# N32H7xx register map
Vendor: Nationstech Ltd.; File version: 1.0
CPU: CM7 r1p1, little endian, MPU, FPU, 4 interrupt priority bits
Registers are 32-bit, read-write, reset 0x0 unless marked. A register's access mark holds for its fields unless they carry their own. Offsets are from the block's base; [hi:lo] are bit positions; {n}, {i} and the like mark numbered series.

## GPU — Graphics processing unit
Base 0x50040000
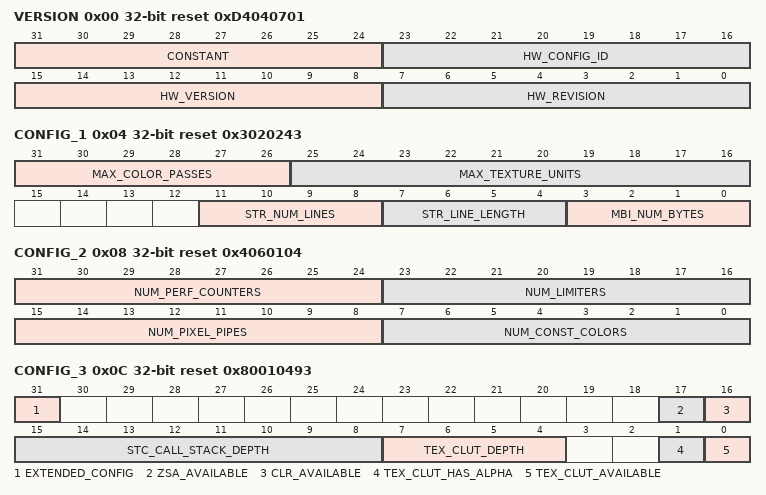
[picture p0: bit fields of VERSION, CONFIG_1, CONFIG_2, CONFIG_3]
0x00 VERSION ro reset 0xD4040701
  [31:24] CONSTANT, [23:16] HW_CONFIG_ID, [15:8] HW_VERSION, [7:0] HW_REVISION
0x04 CONFIG_1 ro reset 0x3020243
  [31:26] MAX_COLOR_PASSES, [25:16] MAX_TEXTURE_UNITS, [11:8] STR_NUM_LINES, [7:4] STR_LINE_LENGTH, [3:0] MBI_NUM_BYTES
0x08 CONFIG_2 ro reset 0x4060104
  [31:24] NUM_PERF_COUNTERS, [23:16] NUM_LIMITERS, [15:8] NUM_PIXEL_PIPES, [7:0] NUM_CONST_COLORS
0x0C CONFIG_3 ro reset 0x80010493
  [31] EXTENDED_CONFIG, [17] ZSA_AVAILABLE, [16] CLR_AVAILABLE, [15:8] STC_CALL_STACK_DEPTH, [7:4] TEX_CLUT_DEPTH, [1] TEX_CLUT_HAS_ALPHA, [0] TEX_CLUT_AVAILABLE
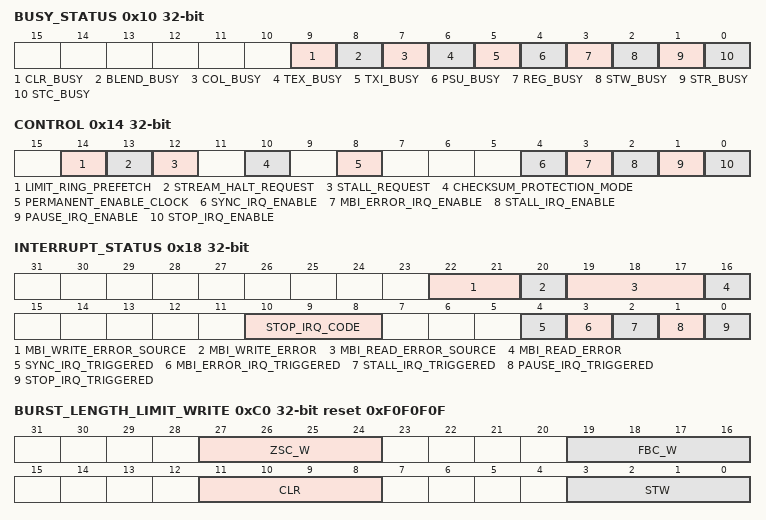
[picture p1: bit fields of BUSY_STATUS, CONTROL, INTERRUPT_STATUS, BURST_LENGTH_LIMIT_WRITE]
0x10 BUSY_STATUS ro
  [9] CLR_BUSY, [8] BLEND_BUSY, [7] COL_BUSY, [6] TEX_BUSY, [5] TXI_BUSY, [4] PSU_BUSY, [3] REG_BUSY, [2] STW_BUSY, [1] STR_BUSY, [0] STC_BUSY
0x14 CONTROL
  [14] LIMIT_RING_PREFETCH, [13] STREAM_HALT_REQUEST, [12] STALL_REQUEST, [10] CHECKSUM_PROTECTION_MODE, [8] PERMANENT_ENABLE_CLOCK, [4] SYNC_IRQ_ENABLE, [3] MBI_ERROR_IRQ_ENABLE, [2] STALL_IRQ_ENABLE, [1] PAUSE_IRQ_ENABLE, [0] STOP_IRQ_ENABLE
0x18 INTERRUPT_STATUS
  [22:21] MBI_WRITE_ERROR_SOURCE ro, [20] MBI_WRITE_ERROR ro, [19:17] MBI_READ_ERROR_SOURCE ro, [16] MBI_READ_ERROR ro, [10:8] STOP_IRQ_CODE ro, [4] SYNC_IRQ_TRIGGERED write-1-clears, [3] MBI_ERROR_IRQ_TRIGGERED write-1-clears, [2] STALL_IRQ_TRIGGERED write-1-clears, [1] PAUSE_IRQ_TRIGGERED write-1-clears, [0] STOP_IRQ_TRIGGERED write-1-clears
0x1C STREAM_ADDRESS
  [31:2] STREAM_ADDRESS
0x20 RING_PAUSE_ADDRESS
  [31:2] RING_PAUSE_ADDRESS
0x24 CURRENT_RING_ADDRESS
  [31:2] CURRENT_RING_ADDRESS
0x28 CURRENT_STREAM_ADDRESS
  [31:2] CURRENT_STREAM_ADDRESS
0x2C CURRENT_CHECKSUM
  [31:0] CURRENT_REFERENCE_CHECKSUM
{0x30+4i} SYNC_ID_{i} (i=0..2)
  [31:0] SYNCHRONIZATION_ID_{i}
0x3C CALL_STACK_POINTER
  [1:0] CALL_STACK_POINTER
{0x40+4i} CALL_STACK_ENTRY_{i} (i=0..7)
  [31:2] CALL_STACK_ENTRY_{i}
{0x80+4i} PERFORMANCE_COUNTER_VALUES_{i} ro (i=0..3)
0xC0 BURST_LENGTH_LIMIT_WRITE reset 0xF0F0F0F
  [27:24] ZSC_W, [19:16] FBC_W, [11:8] CLR, [3:0] STW
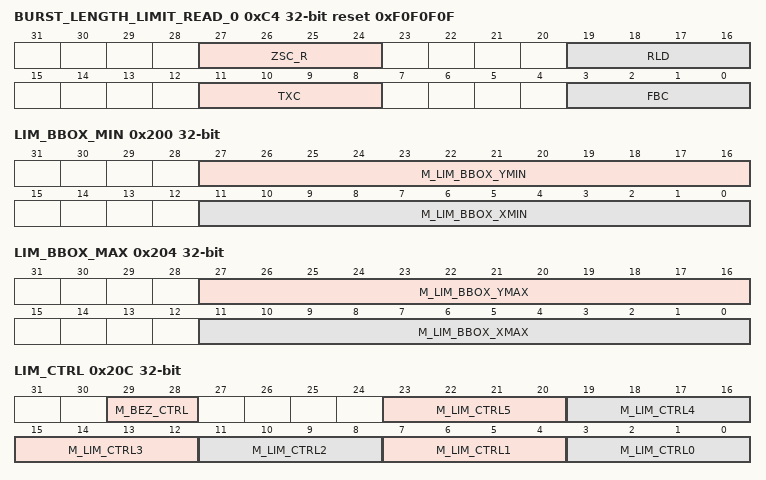
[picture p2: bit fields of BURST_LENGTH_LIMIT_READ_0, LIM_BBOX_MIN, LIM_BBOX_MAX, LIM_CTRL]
0xC4 BURST_LENGTH_LIMIT_READ_0 reset 0xF0F0F0F
  [27:24] ZSC_R, [19:16] RLD, [11:8] TXC, [3:0] FBC
0xC8 BURST_LENGTH_LIMIT_READ_1 reset 0xF
  [3:0] STR
0x200 LIM_BBOX_MIN
  [27:16] M_LIM_BBOX_YMIN, [11:0] M_LIM_BBOX_XMIN
0x204 LIM_BBOX_MAX
  [27:16] M_LIM_BBOX_YMAX, [11:0] M_LIM_BBOX_XMAX
0x208 LIM_START
  [27:16] M_LIM_START_Y
0x20C LIM_CTRL
  [29:28] M_BEZ_CTRL, [4n+3:4n] M_LIM_CTRL{n} (n=0..5)
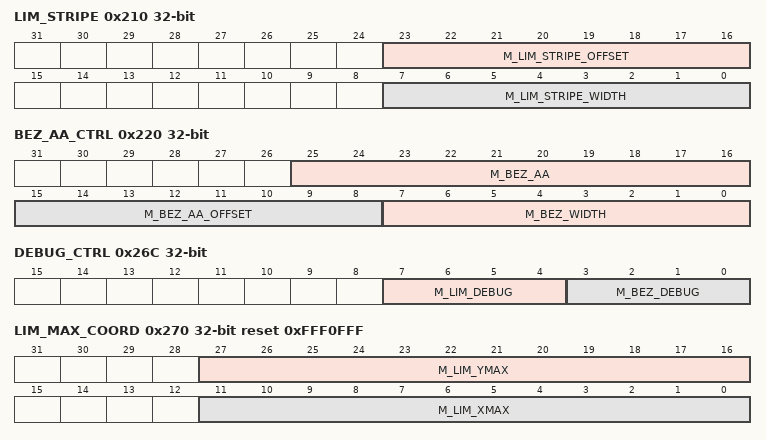
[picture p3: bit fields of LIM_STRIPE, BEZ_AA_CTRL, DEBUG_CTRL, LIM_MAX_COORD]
0x210 LIM_STRIPE
  [23:16] M_LIM_STRIPE_OFFSET, [7:0] M_LIM_STRIPE_WIDTH
0x214 BEZ_CTRL
  [5:0] M_BEZ_LIM_SCALE
0x218 BEZ_VOFF_0
  [31:0] M_BEZ_VOFF_0
0x21C BEZ_VOFF_1
  [31:0] M_BEZ_VOFF_1
0x220 BEZ_AA_CTRL
  [25:16] M_BEZ_AA, [15:8] M_BEZ_AA_OFFSET, [7:0] M_BEZ_WIDTH
{0x224+0xC*i} LIM_VSTART_{i} (i=0..5)
  [31:0] M_LIM_VSTART_{i}
{0x228+0xC*i} LIM_DX_{i} (i=0..5)
  [19:0] M_LIM_DX_{i}
{0x22C+0xC*i} LIM_DY_{i} (i=0..5)
  [19:0] M_LIM_DY_{i}
0x26C DEBUG_CTRL
  [7:4] M_LIM_DEBUG, [3:0] M_BEZ_DEBUG
0x270 LIM_MAX_COORD reset 0xFFF0FFF
  [27:16] M_LIM_YMAX, [11:0] M_LIM_XMAX
0x300 TXA_U_OFFSET_0
  [31:0] M_TXA_U_OFFSET_0
0x304 TXA_V_OFFSET_0
  [31:0] M_TXA_V_OFFSET_0
0x308 TXA_DUX_0 reset 0x3F800000
  [31:0] M_TXA_DUX_0
0x30C TXA_DUY_0
  [31:0] M_TXA_DUY_0
0x310 TXA_DVX_0
  [31:0] M_TXA_DVX_0
0x314 TXA_DVY_0 reset 0x3F800000
  [31:0] M_TXA_DVY_0
0x318 TXA_U_OFFSET_1
  [31:0] M_TXA_U_OFFSET_1
0x31C TXA_V_OFFSET_1
  [31:0] M_TXA_V_OFFSET_1
0x320 TXA_DUX_1 reset 0x3F800000
  [31:0] M_TXA_DUX_1
0x324 TXA_DUY_1
  [31:0] M_TXA_DUY_1
0x328 TXA_DVX_1
  [31:0] M_TXA_DVX_1
0x32C TXA_DVY_1 reset 0x3F800000
  [31:0] M_TXA_DVY_1
0x408 TXA_Z_OFFSET
  [31:0] M_TXA_Z_OFFSET
0x40C TXA_DZX
  [31:0] M_TXA_DZX
0x410 TXA_DZY
  [31:0] M_TXA_DZY
0x414 TXA_Z_RHW_OFFSET reset 0x3F800000
  [31:0] M_TXA_Z_RHW_OFFSET
0x418 TXA_Z_DRHWX
  [31:0] M_TXA_Z_DRHWX
0x41C TXA_Z_DRHWY
  [31:0] M_TXA_Z_DRHWY
0x420 TXA_RHW_OFFSET_0 reset 0x3F800000
  [31:0] M_TXA_RHW_OFFSET_0
0x424 TXA_DRHWX_0
  [31:0] M_TXA_DRHWX_0
0x428 TXA_DRHWY_0
  [31:0] M_TXA_DRHWY_0
0x42C TXA_RHW_OFFSET_1 reset 0x3F800000
  [31:0] M_TXA_RHW_OFFSET_1
0x430 TXA_DRHWX_1
  [31:0] M_TXA_DRHWX_1
0x434 TXA_DRHWY_1
  [31:0] M_TXA_DRHWY_1
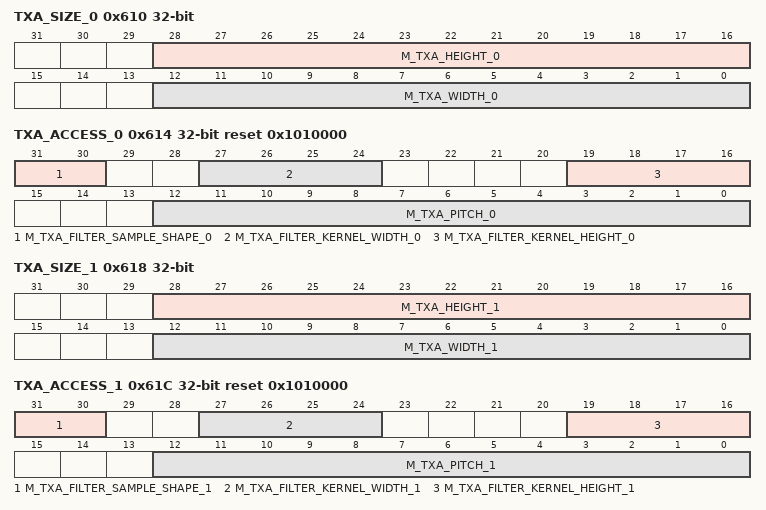
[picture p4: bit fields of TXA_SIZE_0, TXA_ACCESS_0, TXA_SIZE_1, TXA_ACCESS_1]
0x610 TXA_SIZE_0
  [28:16] M_TXA_HEIGHT_0, [12:0] M_TXA_WIDTH_0
0x614 TXA_ACCESS_0 reset 0x1010000
  [31:30] M_TXA_FILTER_SAMPLE_SHAPE_0, [27:24] M_TXA_FILTER_KERNEL_WIDTH_0, [19:16] M_TXA_FILTER_KERNEL_HEIGHT_0, [12:0] M_TXA_PITCH_0
0x618 TXA_SIZE_1
  [28:16] M_TXA_HEIGHT_1, [12:0] M_TXA_WIDTH_1
0x61C TXA_ACCESS_1 reset 0x1010000
  [31:30] M_TXA_FILTER_SAMPLE_SHAPE_1, [27:24] M_TXA_FILTER_KERNEL_WIDTH_1, [19:16] M_TXA_FILTER_KERNEL_HEIGHT_1, [12:0] M_TXA_PITCH_1
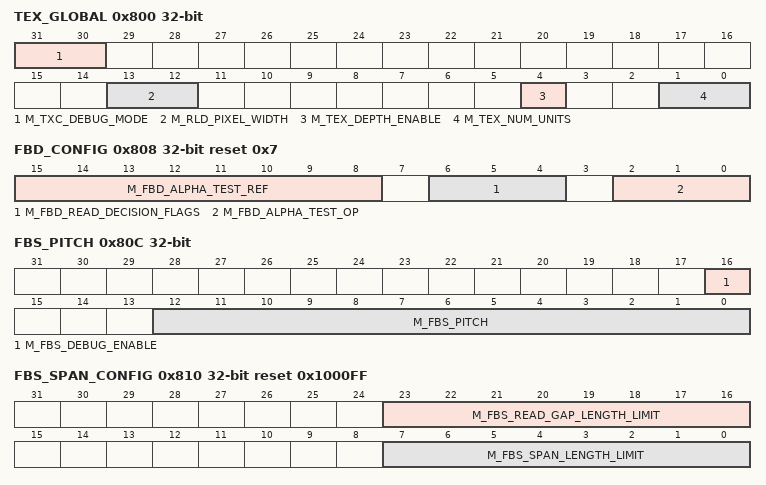
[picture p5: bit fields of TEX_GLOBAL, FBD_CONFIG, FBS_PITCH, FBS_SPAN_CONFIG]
0x800 TEX_GLOBAL
  [31:30] M_TXC_DEBUG_MODE, [13:12] M_RLD_PIXEL_WIDTH, [4] M_TEX_DEPTH_ENABLE, [1:0] M_TEX_NUM_UNITS
0x804 COL_GLOBAL reset 0x1
  [2:0] M_COL_NUM_PASSES
0x808 FBD_CONFIG reset 0x7
  [15:8] M_FBD_ALPHA_TEST_REF, [6:4] M_FBD_READ_DECISION_FLAGS, [2:0] M_FBD_ALPHA_TEST_OP
0x80C FBS_PITCH
  [16] M_FBS_DEBUG_ENABLE, [12:0] M_FBS_PITCH
0x810 FBS_SPAN_CONFIG reset 0x1000FF
  [23:16] M_FBS_READ_GAP_LENGTH_LIMIT, [7:0] M_FBS_SPAN_LENGTH_LIMIT
0x814 RLD_START_ADDRESS
  [31:0] M_RLD_START_ADDRESS
{0x818+4i} COL_CONST_COLOR_{i} reset 0xFFFFFFFF (i=0..3)
  [31:0] M_COL_CONST_COLOR_{i}
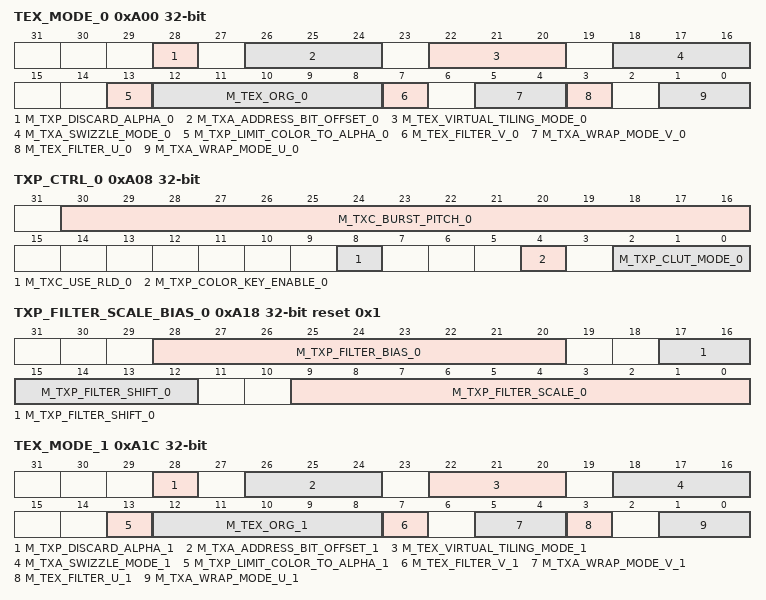
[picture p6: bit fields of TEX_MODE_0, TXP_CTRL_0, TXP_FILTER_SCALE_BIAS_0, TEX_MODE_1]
0xA00 TEX_MODE_0
  [28] M_TXP_DISCARD_ALPHA_0, [26:24] M_TXA_ADDRESS_BIT_OFFSET_0, [22:20] M_TEX_VIRTUAL_TILING_MODE_0, [18:16] M_TXA_SWIZZLE_MODE_0, [13] M_TXP_LIMIT_COLOR_TO_ALPHA_0, [12:8] M_TEX_ORG_0, [7] M_TEX_FILTER_V_0, [5:4] M_TXA_WRAP_MODE_V_0, [3] M_TEX_FILTER_U_0, [1:0] M_TXA_WRAP_MODE_U_0
0xA04 TXC_START_ADDRESS_0
  [31:0] M_TXC_START_ADDRESS_0
0xA08 TXP_CTRL_0
  [30:16] M_TXC_BURST_PITCH_0, [8] M_TXC_USE_RLD_0, [4] M_TXP_COLOR_KEY_ENABLE_0, [2:0] M_TXP_CLUT_MODE_0
0xA0C TXP_CLUT_OFFSET_0
  [8:0] M_TXP_CLUT_OFFSET_0
0xA10 TXP_COLOR_KEY_0
  [23:0] M_TXP_COLOR_KEY_0
0xA14 TXP_FILL_COLOR_0
  [31:0] M_TXP_FILL_COLOR_0
0xA18 TXP_FILTER_SCALE_BIAS_0 reset 0x1
  [28:20] M_TXP_FILTER_BIAS_0, [17:12] M_TXP_FILTER_SHIFT_0, [9:0] M_TXP_FILTER_SCALE_0
0xA1C TEX_MODE_1
  [28] M_TXP_DISCARD_ALPHA_1, [26:24] M_TXA_ADDRESS_BIT_OFFSET_1, [22:20] M_TEX_VIRTUAL_TILING_MODE_1, [18:16] M_TXA_SWIZZLE_MODE_1, [13] M_TXP_LIMIT_COLOR_TO_ALPHA_1, [12:8] M_TEX_ORG_1, [7] M_TEX_FILTER_V_1, [5:4] M_TXA_WRAP_MODE_V_1, [3] M_TEX_FILTER_U_1, [1:0] M_TXA_WRAP_MODE_U_1
0xA20 TXC_START_ADDRESS_1
  [31:0] M_TXC_START_ADDRESS_1
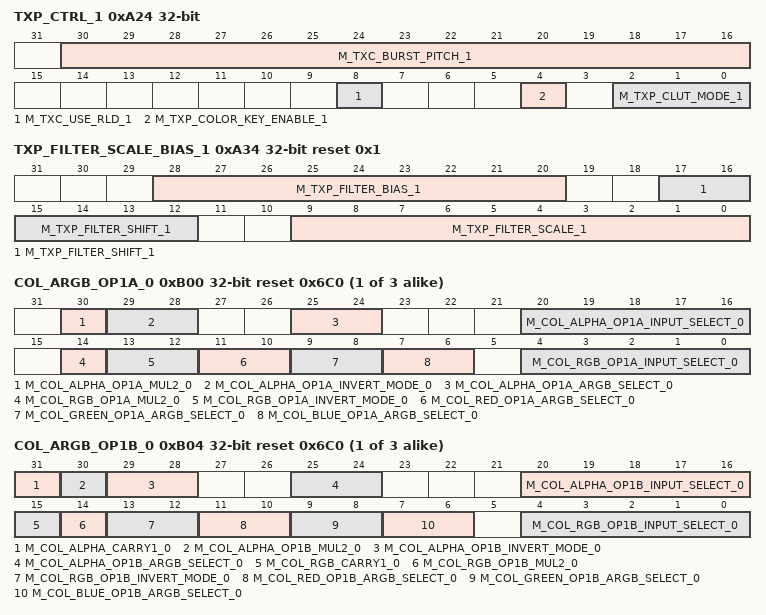
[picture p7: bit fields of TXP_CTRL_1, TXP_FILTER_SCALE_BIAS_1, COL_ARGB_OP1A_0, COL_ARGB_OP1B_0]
0xA24 TXP_CTRL_1
  [30:16] M_TXC_BURST_PITCH_1, [8] M_TXC_USE_RLD_1, [4] M_TXP_COLOR_KEY_ENABLE_1, [2:0] M_TXP_CLUT_MODE_1
0xA28 TXP_CLUT_OFFSET_1
  [8:0] M_TXP_CLUT_OFFSET_1
0xA2C TXP_COLOR_KEY_1
  [23:0] M_TXP_COLOR_KEY_1
0xA30 TXP_FILL_COLOR_1
  [31:0] M_TXP_FILL_COLOR_1
0xA34 TXP_FILTER_SCALE_BIAS_1 reset 0x1
  [28:20] M_TXP_FILTER_BIAS_1, [17:12] M_TXP_FILTER_SHIFT_1, [9:0] M_TXP_FILTER_SCALE_1
{0xB00+0x18*i} COL_ARGB_OP1A_{i} reset 0x6C0 (i=0..2)
  [30] M_COL_ALPHA_OP1A_MUL2_{i}, [29:28] M_COL_ALPHA_OP1A_INVERT_MODE_{i}, [25:24] M_COL_ALPHA_OP1A_ARGB_SELECT_{i}, [20:16] M_COL_ALPHA_OP1A_INPUT_SELECT_{i}, [14] M_COL_RGB_OP1A_MUL2_{i}, [13:12] M_COL_RGB_OP1A_INVERT_MODE_{i}, [11:10] M_COL_RED_OP1A_ARGB_SELECT_{i}, [9:8] M_COL_GREEN_OP1A_ARGB_SELECT_{i}, [7:6] M_COL_BLUE_OP1A_ARGB_SELECT_{i}, [4:0] M_COL_RGB_OP1A_INPUT_SELECT_{i}
{0xB04+0x18*i} COL_ARGB_OP1B_{i} reset 0x6C0 (i=0..2)
  [31] M_COL_ALPHA_CARRY1_{i}, [30] M_COL_ALPHA_OP1B_MUL2_{i}, [29:28] M_COL_ALPHA_OP1B_INVERT_MODE_{i}, [25:24] M_COL_ALPHA_OP1B_ARGB_SELECT_{i}, [20:16] M_COL_ALPHA_OP1B_INPUT_SELECT_{i}, [15] M_COL_RGB_CARRY1_{i}, [14] M_COL_RGB_OP1B_MUL2_{i}, [13:12] M_COL_RGB_OP1B_INVERT_MODE_{i}, [11:10] M_COL_RED_OP1B_ARGB_SELECT_{i}, [9:8] M_COL_GREEN_OP1B_ARGB_SELECT_{i}, [7:6] M_COL_BLUE_OP1B_ARGB_SELECT_{i}, [4:0] M_COL_RGB_OP1B_INPUT_SELECT_{i}
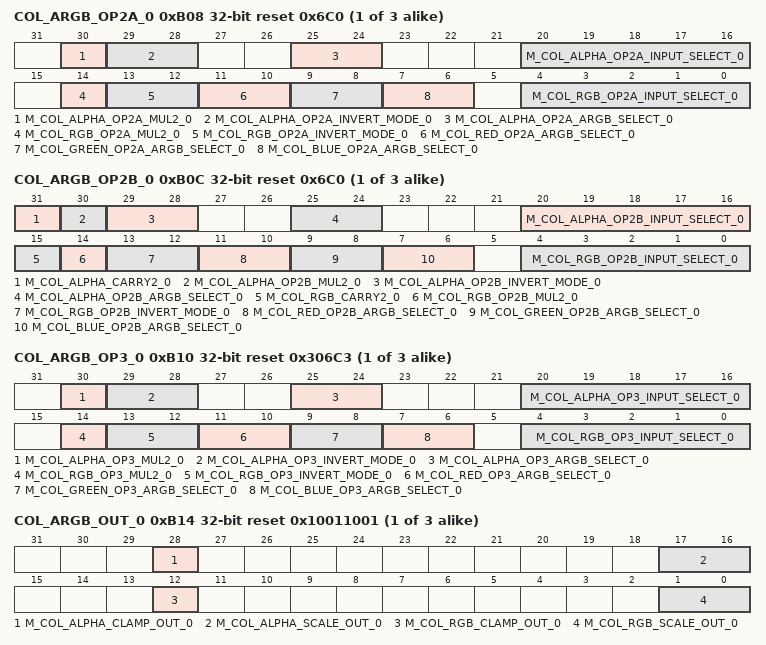
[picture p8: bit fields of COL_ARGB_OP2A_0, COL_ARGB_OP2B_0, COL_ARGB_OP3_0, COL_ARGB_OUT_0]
{0xB08+0x18*i} COL_ARGB_OP2A_{i} reset 0x6C0 (i=0..2)
  [30] M_COL_ALPHA_OP2A_MUL2_{i}, [29:28] M_COL_ALPHA_OP2A_INVERT_MODE_{i}, [25:24] M_COL_ALPHA_OP2A_ARGB_SELECT_{i}, [20:16] M_COL_ALPHA_OP2A_INPUT_SELECT_{i}, [14] M_COL_RGB_OP2A_MUL2_{i}, [13:12] M_COL_RGB_OP2A_INVERT_MODE_{i}, [11:10] M_COL_RED_OP2A_ARGB_SELECT_{i}, [9:8] M_COL_GREEN_OP2A_ARGB_SELECT_{i}, [7:6] M_COL_BLUE_OP2A_ARGB_SELECT_{i}, [4:0] M_COL_RGB_OP2A_INPUT_SELECT_{i}
{0xB0C+0x18*i} COL_ARGB_OP2B_{i} reset 0x6C0 (i=0..2)
  [31] M_COL_ALPHA_CARRY2_{i}, [30] M_COL_ALPHA_OP2B_MUL2_{i}, [29:28] M_COL_ALPHA_OP2B_INVERT_MODE_{i}, [25:24] M_COL_ALPHA_OP2B_ARGB_SELECT_{i}, [20:16] M_COL_ALPHA_OP2B_INPUT_SELECT_{i}, [15] M_COL_RGB_CARRY2_{i}, [14] M_COL_RGB_OP2B_MUL2_{i}, [13:12] M_COL_RGB_OP2B_INVERT_MODE_{i}, [11:10] M_COL_RED_OP2B_ARGB_SELECT_{i}, [9:8] M_COL_GREEN_OP2B_ARGB_SELECT_{i}, [7:6] M_COL_BLUE_OP2B_ARGB_SELECT_{i}, [4:0] M_COL_RGB_OP2B_INPUT_SELECT_{i}
{0xB10+0x18*i} COL_ARGB_OP3_{i} reset 0x306C3 (i=0..2)
  [30] M_COL_ALPHA_OP3_MUL2_{i}, [29:28] M_COL_ALPHA_OP3_INVERT_MODE_{i}, [25:24] M_COL_ALPHA_OP3_ARGB_SELECT_{i}, [20:16] M_COL_ALPHA_OP3_INPUT_SELECT_{i}, [14] M_COL_RGB_OP3_MUL2_{i}, [13:12] M_COL_RGB_OP3_INVERT_MODE_{i}, [11:10] M_COL_RED_OP3_ARGB_SELECT_{i}, [9:8] M_COL_GREEN_OP3_ARGB_SELECT_{i}, [7:6] M_COL_BLUE_OP3_ARGB_SELECT_{i}, [4:0] M_COL_RGB_OP3_INPUT_SELECT_{i}
{0xB14+0x18*i} COL_ARGB_OUT_{i} reset 0x10011001 (i=0..2)
  [28] M_COL_ALPHA_CLAMP_OUT_{i}, [17:16] M_COL_ALPHA_SCALE_OUT_{i}, [12] M_COL_RGB_CLAMP_OUT_{i}, [1:0] M_COL_RGB_SCALE_OUT_{i}
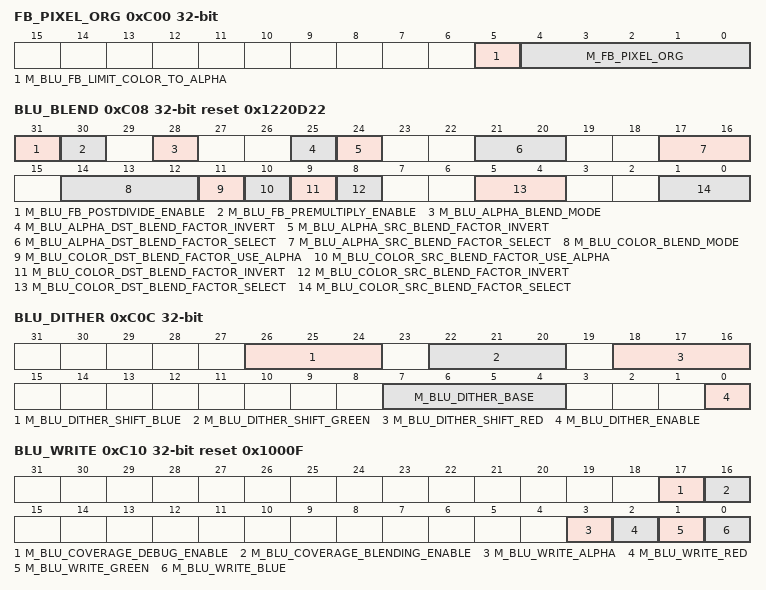
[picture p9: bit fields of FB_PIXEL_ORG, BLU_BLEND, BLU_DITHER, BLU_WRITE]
0xC00 FB_PIXEL_ORG
  [5] M_BLU_FB_LIMIT_COLOR_TO_ALPHA, [4:0] M_FB_PIXEL_ORG
0xC04 FBC_START_ADDRESS
  [31:0] M_FBC_START_ADDRESS
0xC08 BLU_BLEND reset 0x1220D22
  [31] M_BLU_FB_POSTDIVIDE_ENABLE, [30] M_BLU_FB_PREMULTIPLY_ENABLE, [28] M_BLU_ALPHA_BLEND_MODE, [25] M_BLU_ALPHA_DST_BLEND_FACTOR_INVERT, [24] M_BLU_ALPHA_SRC_BLEND_FACTOR_INVERT, [21:20] M_BLU_ALPHA_DST_BLEND_FACTOR_SELECT, [17:16] M_BLU_ALPHA_SRC_BLEND_FACTOR_SELECT, [14:12] M_BLU_COLOR_BLEND_MODE, [11] M_BLU_COLOR_DST_BLEND_FACTOR_USE_ALPHA, [10] M_BLU_COLOR_SRC_BLEND_FACTOR_USE_ALPHA, [9] M_BLU_COLOR_DST_BLEND_FACTOR_INVERT, [8] M_BLU_COLOR_SRC_BLEND_FACTOR_INVERT, [5:4] M_BLU_COLOR_DST_BLEND_FACTOR_SELECT, [1:0] M_BLU_COLOR_SRC_BLEND_FACTOR_SELECT
0xC0C BLU_DITHER
  [26:24] M_BLU_DITHER_SHIFT_BLUE, [22:20] M_BLU_DITHER_SHIFT_GREEN, [18:16] M_BLU_DITHER_SHIFT_RED, [7:4] M_BLU_DITHER_BASE, [0] M_BLU_DITHER_ENABLE
0xC10 BLU_WRITE reset 0x1000F
  [17] M_BLU_COVERAGE_DEBUG_ENABLE, [16] M_BLU_COVERAGE_BLENDING_ENABLE, [3] M_BLU_WRITE_ALPHA, [2] M_BLU_WRITE_RED, [1] M_BLU_WRITE_GREEN, [0] M_BLU_WRITE_BLUE
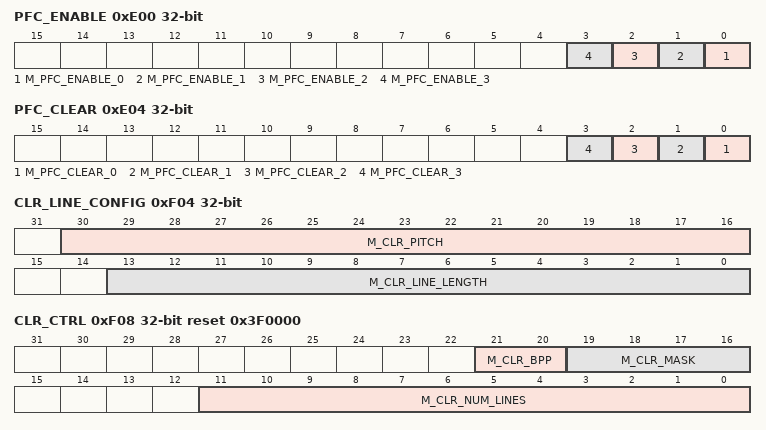
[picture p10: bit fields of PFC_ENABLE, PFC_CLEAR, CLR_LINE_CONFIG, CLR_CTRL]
0xE00 PFC_ENABLE
  [n] M_PFC_ENABLE_{n} (n=0..3)
0xE04 PFC_CLEAR
  [n] M_PFC_CLEAR_{n} (n=0..3)
{0xE08+4i} PFC_EVENT_SELECT_{i} reset 0x3B (i=0..3)
  [6:0] M_PFC_EVENT_SELECT_{i}
0xF00 CLR_VALUE reset 0xFFFFFFFF
  [31:0] M_CLR_VALUE
0xF04 CLR_LINE_CONFIG
  [30:16] M_CLR_PITCH, [13:0] M_CLR_LINE_LENGTH
0xF08 CLR_CTRL reset 0x3F0000
  [21:20] M_CLR_BPP, [19:16] M_CLR_MASK, [11:0] M_CLR_NUM_LINES
0xF0C CLR_START_ADDRESS
  [31:0] M_CLR_START_ADDRESS
0x2000 LUT — Lookup table entry
  [31:0] LUT_ENTRY
